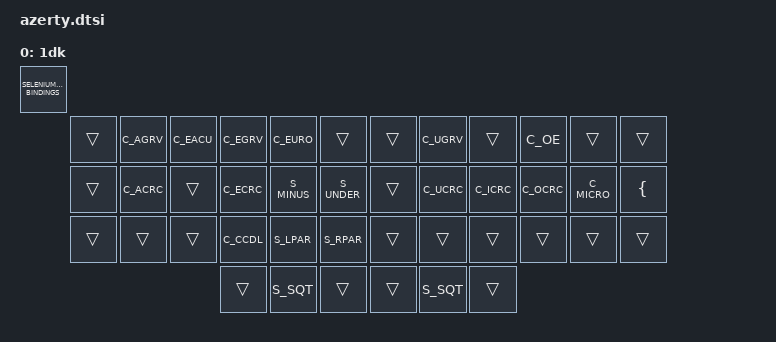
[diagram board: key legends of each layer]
#define DK_LAYER EXTRA_LAYERS_START_INDEX

// Standard base layer, but SQT becomes a dead key
&base_layer {
  display-name = "Base";
  bindings = <SELENIUM_KEYMAP_BINDINGS(
    &kp TAB     ,  &kp Q &kp W &kp E &kp R &kp T  ,  &kp Y  &kp U  &kp I     &kp O   &kp P     ,  &kp BACKSPACE  ,
    &kp ESCAPE  ,  &H4 A &H3 S &H2 D &H1 F &kp G  ,  &kp H  &H1 J  &H2 K     &H3 L   &H4 SEMI  ,  &dead_key      ,
    &kp LSHIFT  ,  &kp Z &kp X &kp C &kp V &kp B  ,  &kp N  &kp M  &kp COMMA &kp DOT &kp FSLH  ,  &kp RSHIFT     ,
        LTHUMB_TUCK , LTHUMB_HOME , LTHUMB_REACH  ,  RTHUMB_REACH , RTHUMB_HOME , RTHUMB_TUCK
  )>;
};

/ {
  behaviors {
    TWO_LEVEL_KEY(dead_key, &EZ_SL(DK_LAYER), S_PRCNT) // ' % (1dk)
  };

  // Extra layers defined specifically for this keymap, appended to the base keymap.
  keymap {
    compatible = "zmk,keymap";

    dead_key_layer {
      display-name = "1dk";
      bindings = <SELENIUM_KEYMAP_BINDINGS(
        &trans  ,  C_AGRV  C_EACU  C_EGRV  C_EURO  &trans   ,  &trans  C_UGRV  &trans  C_OE    &trans  ,  &trans   ,
        &trans  ,  C_ACRC  &trans  C_ECRC  S_MINUS S_UNDER  ,  &trans  C_UCRC  C_ICRC  C_OCRC  C_MICRO ,  &kp LBRC ,
        &trans  ,  &trans  &trans  C_CCDL  S_LPAR  S_RPAR   ,  &trans  &trans  &trans  &trans  &trans  ,  &trans   ,
                                  &trans , S_SQT , &trans   ,  &trans , S_SQT , &trans
      )>;
    };
  };
};
